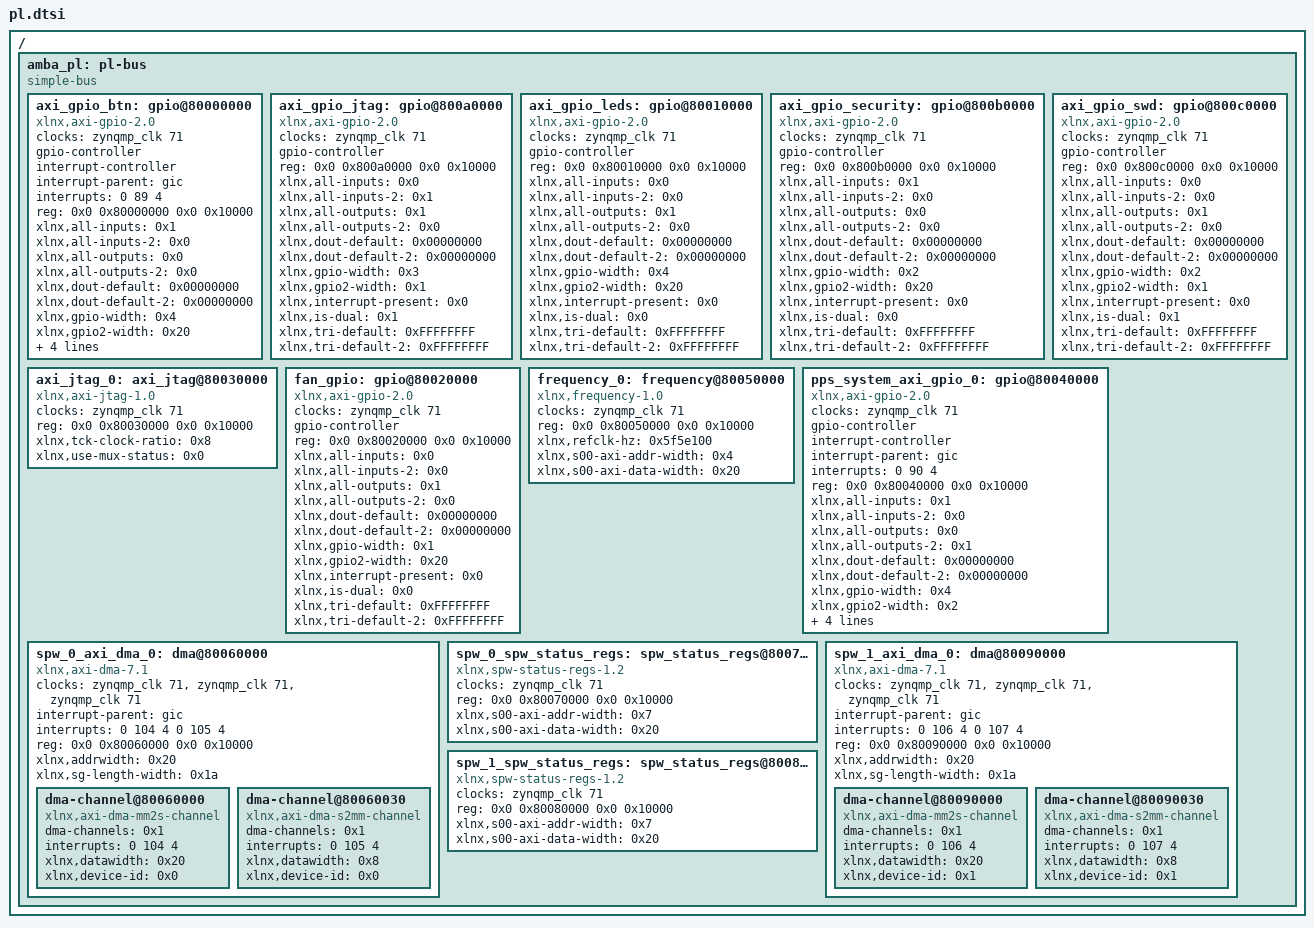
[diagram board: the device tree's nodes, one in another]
/*
 * CAUTION: This file is automatically generated by Xilinx.
 * Version: XSCT 
 * Today is: Sun Feb  1 17:45:51 2026
 */


/ {
	amba_pl: pl-bus {
		#address-cells = <2>;
		#size-cells = <2>;
		compatible = "simple-bus";
		ranges ;
		axi_gpio_btn: gpio@80000000 {
			#gpio-cells = <2>;
			#interrupt-cells = <2>;
			clock-names = "s_axi_aclk";
			clocks = <&zynqmp_clk 71>;
			compatible = "xlnx,axi-gpio-2.0", "xlnx,xps-gpio-1.00.a";
			gpio-controller ;
			interrupt-controller ;
			interrupt-names = "ip2intc_irpt";
			interrupt-parent = <&gic>;
			interrupts = <0 89 4>;
			reg = <0x0 0x80000000 0x0 0x10000>;
			xlnx,all-inputs = <0x1>;
			xlnx,all-inputs-2 = <0x0>;
			xlnx,all-outputs = <0x0>;
			xlnx,all-outputs-2 = <0x0>;
			xlnx,dout-default = <0x00000000>;
			xlnx,dout-default-2 = <0x00000000>;
			xlnx,gpio-width = <0x4>;
			xlnx,gpio2-width = <0x20>;
			xlnx,interrupt-present = <0x1>;
			xlnx,is-dual = <0x0>;
			xlnx,tri-default = <0xFFFFFFFF>;
			xlnx,tri-default-2 = <0xFFFFFFFF>;
		};
		axi_gpio_jtag: gpio@800a0000 {
			#gpio-cells = <2>;
			clock-names = "s_axi_aclk";
			clocks = <&zynqmp_clk 71>;
			compatible = "xlnx,axi-gpio-2.0", "xlnx,xps-gpio-1.00.a";
			gpio-controller ;
			reg = <0x0 0x800a0000 0x0 0x10000>;
			xlnx,all-inputs = <0x0>;
			xlnx,all-inputs-2 = <0x1>;
			xlnx,all-outputs = <0x1>;
			xlnx,all-outputs-2 = <0x0>;
			xlnx,dout-default = <0x00000000>;
			xlnx,dout-default-2 = <0x00000000>;
			xlnx,gpio-width = <0x3>;
			xlnx,gpio2-width = <0x1>;
			xlnx,interrupt-present = <0x0>;
			xlnx,is-dual = <0x1>;
			xlnx,tri-default = <0xFFFFFFFF>;
			xlnx,tri-default-2 = <0xFFFFFFFF>;
		};
		axi_gpio_leds: gpio@80010000 {
			#gpio-cells = <2>;
			clock-names = "s_axi_aclk";
			clocks = <&zynqmp_clk 71>;
			compatible = "xlnx,axi-gpio-2.0", "xlnx,xps-gpio-1.00.a";
			gpio-controller ;
			reg = <0x0 0x80010000 0x0 0x10000>;
			xlnx,all-inputs = <0x0>;
			xlnx,all-inputs-2 = <0x0>;
			xlnx,all-outputs = <0x1>;
			xlnx,all-outputs-2 = <0x0>;
			xlnx,dout-default = <0x00000000>;
			xlnx,dout-default-2 = <0x00000000>;
			xlnx,gpio-width = <0x4>;
			xlnx,gpio2-width = <0x20>;
			xlnx,interrupt-present = <0x0>;
			xlnx,is-dual = <0x0>;
			xlnx,tri-default = <0xFFFFFFFF>;
			xlnx,tri-default-2 = <0xFFFFFFFF>;
		};
		axi_gpio_security: gpio@800b0000 {
			#gpio-cells = <2>;
			clock-names = "s_axi_aclk";
			clocks = <&zynqmp_clk 71>;
			compatible = "xlnx,axi-gpio-2.0", "xlnx,xps-gpio-1.00.a";
			gpio-controller ;
			reg = <0x0 0x800b0000 0x0 0x10000>;
			xlnx,all-inputs = <0x1>;
			xlnx,all-inputs-2 = <0x0>;
			xlnx,all-outputs = <0x0>;
			xlnx,all-outputs-2 = <0x0>;
			xlnx,dout-default = <0x00000000>;
			xlnx,dout-default-2 = <0x00000000>;
			xlnx,gpio-width = <0x2>;
			xlnx,gpio2-width = <0x20>;
			xlnx,interrupt-present = <0x0>;
			xlnx,is-dual = <0x0>;
			xlnx,tri-default = <0xFFFFFFFF>;
			xlnx,tri-default-2 = <0xFFFFFFFF>;
		};
		axi_gpio_swd: gpio@800c0000 {
			#gpio-cells = <2>;
			clock-names = "s_axi_aclk";
			clocks = <&zynqmp_clk 71>;
			compatible = "xlnx,axi-gpio-2.0", "xlnx,xps-gpio-1.00.a";
			gpio-controller ;
			reg = <0x0 0x800c0000 0x0 0x10000>;
			xlnx,all-inputs = <0x0>;
			xlnx,all-inputs-2 = <0x0>;
			xlnx,all-outputs = <0x1>;
			xlnx,all-outputs-2 = <0x0>;
			xlnx,dout-default = <0x00000000>;
			xlnx,dout-default-2 = <0x00000000>;
			xlnx,gpio-width = <0x2>;
			xlnx,gpio2-width = <0x1>;
			xlnx,interrupt-present = <0x0>;
			xlnx,is-dual = <0x1>;
			xlnx,tri-default = <0xFFFFFFFF>;
			xlnx,tri-default-2 = <0xFFFFFFFF>;
		};
		axi_jtag_0: axi_jtag@80030000 {
			clock-names = "s_axi_aclk";
			clocks = <&zynqmp_clk 71>;
			compatible = "xlnx,axi-jtag-1.0";
			reg = <0x0 0x80030000 0x0 0x10000>;
			xlnx,tck-clock-ratio = <0x8>;
			xlnx,use-mux-status = <0x0>;
		};
		fan_gpio: gpio@80020000 {
			#gpio-cells = <2>;
			clock-names = "s_axi_aclk";
			clocks = <&zynqmp_clk 71>;
			compatible = "xlnx,axi-gpio-2.0", "xlnx,xps-gpio-1.00.a";
			gpio-controller ;
			reg = <0x0 0x80020000 0x0 0x10000>;
			xlnx,all-inputs = <0x0>;
			xlnx,all-inputs-2 = <0x0>;
			xlnx,all-outputs = <0x1>;
			xlnx,all-outputs-2 = <0x0>;
			xlnx,dout-default = <0x00000000>;
			xlnx,dout-default-2 = <0x00000000>;
			xlnx,gpio-width = <0x1>;
			xlnx,gpio2-width = <0x20>;
			xlnx,interrupt-present = <0x0>;
			xlnx,is-dual = <0x0>;
			xlnx,tri-default = <0xFFFFFFFF>;
			xlnx,tri-default-2 = <0xFFFFFFFF>;
		};
		frequency_0: frequency@80050000 {
			clock-names = "s00_axi_aclk";
			clocks = <&zynqmp_clk 71>;
			compatible = "xlnx,frequency-1.0";
			reg = <0x0 0x80050000 0x0 0x10000>;
			xlnx,refclk-hz = <0x5f5e100>;
			xlnx,s00-axi-addr-width = <0x4>;
			xlnx,s00-axi-data-width = <0x20>;
		};
		pps_system_axi_gpio_0: gpio@80040000 {
			#gpio-cells = <2>;
			#interrupt-cells = <2>;
			clock-names = "s_axi_aclk";
			clocks = <&zynqmp_clk 71>;
			compatible = "xlnx,axi-gpio-2.0", "xlnx,xps-gpio-1.00.a";
			gpio-controller ;
			interrupt-controller ;
			interrupt-names = "ip2intc_irpt";
			interrupt-parent = <&gic>;
			interrupts = <0 90 4>;
			reg = <0x0 0x80040000 0x0 0x10000>;
			xlnx,all-inputs = <0x1>;
			xlnx,all-inputs-2 = <0x0>;
			xlnx,all-outputs = <0x0>;
			xlnx,all-outputs-2 = <0x1>;
			xlnx,dout-default = <0x00000000>;
			xlnx,dout-default-2 = <0x00000000>;
			xlnx,gpio-width = <0x4>;
			xlnx,gpio2-width = <0x2>;
			xlnx,interrupt-present = <0x1>;
			xlnx,is-dual = <0x1>;
			xlnx,tri-default = <0xFFFFFFFF>;
			xlnx,tri-default-2 = <0xFFFFFFFF>;
		};
		spw_0_axi_dma_0: dma@80060000 {
			#dma-cells = <1>;
			clock-names = "m_axi_mm2s_aclk", "m_axi_s2mm_aclk", "s_axi_lite_aclk";
			clocks = <&zynqmp_clk 71>, <&zynqmp_clk 71>, <&zynqmp_clk 71>;
			compatible = "xlnx,axi-dma-7.1", "xlnx,axi-dma-1.00.a";
			interrupt-names = "mm2s_introut", "s2mm_introut";
			interrupt-parent = <&gic>;
			interrupts = <0 104 4 0 105 4>;
			reg = <0x0 0x80060000 0x0 0x10000>;
			xlnx,addrwidth = <0x20>;
			xlnx,sg-length-width = <0x1a>;
			dma-channel@80060000 {
				compatible = "xlnx,axi-dma-mm2s-channel";
				dma-channels = <0x1>;
				interrupts = <0 104 4>;
				xlnx,datawidth = <0x20>;
				xlnx,device-id = <0x0>;
			};
			dma-channel@80060030 {
				compatible = "xlnx,axi-dma-s2mm-channel";
				dma-channels = <0x1>;
				interrupts = <0 105 4>;
				xlnx,datawidth = <0x8>;
				xlnx,device-id = <0x0>;
			};
		};
		spw_0_spw_status_regs: spw_status_regs@80070000 {
			clock-names = "s00_axi_aclk";
			clocks = <&zynqmp_clk 71>;
			compatible = "xlnx,spw-status-regs-1.2";
			reg = <0x0 0x80070000 0x0 0x10000>;
			xlnx,s00-axi-addr-width = <0x7>;
			xlnx,s00-axi-data-width = <0x20>;
		};
		spw_1_axi_dma_0: dma@80090000 {
			#dma-cells = <1>;
			clock-names = "m_axi_mm2s_aclk", "m_axi_s2mm_aclk", "s_axi_lite_aclk";
			clocks = <&zynqmp_clk 71>, <&zynqmp_clk 71>, <&zynqmp_clk 71>;
			compatible = "xlnx,axi-dma-7.1", "xlnx,axi-dma-1.00.a";
			interrupt-names = "mm2s_introut", "s2mm_introut";
			interrupt-parent = <&gic>;
			interrupts = <0 106 4 0 107 4>;
			reg = <0x0 0x80090000 0x0 0x10000>;
			xlnx,addrwidth = <0x20>;
			xlnx,sg-length-width = <0x1a>;
			dma-channel@80090000 {
				compatible = "xlnx,axi-dma-mm2s-channel";
				dma-channels = <0x1>;
				interrupts = <0 106 4>;
				xlnx,datawidth = <0x20>;
				xlnx,device-id = <0x1>;
			};
			dma-channel@80090030 {
				compatible = "xlnx,axi-dma-s2mm-channel";
				dma-channels = <0x1>;
				interrupts = <0 107 4>;
				xlnx,datawidth = <0x8>;
				xlnx,device-id = <0x1>;
			};
		};
		spw_1_spw_status_regs: spw_status_regs@80080000 {
			clock-names = "s00_axi_aclk";
			clocks = <&zynqmp_clk 71>;
			compatible = "xlnx,spw-status-regs-1.2";
			reg = <0x0 0x80080000 0x0 0x10000>;
			xlnx,s00-axi-addr-width = <0x7>;
			xlnx,s00-axi-data-width = <0x20>;
		};
	};
};
